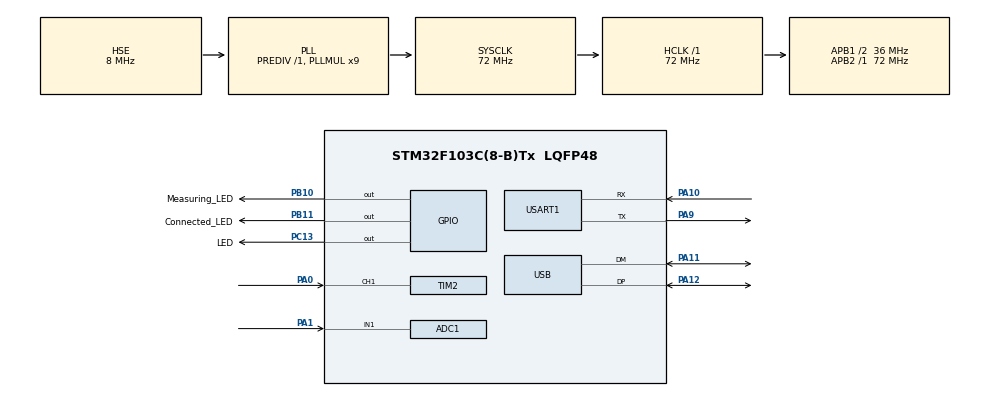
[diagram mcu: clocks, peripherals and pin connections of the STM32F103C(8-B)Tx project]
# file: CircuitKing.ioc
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ADC1.Channel-0\#ChannelRegularConversion=ADC_CHANNEL_1
ADC1.ContinuousConvMode=ENABLE
ADC1.NbrOfConversionFlag=1
ADC1.Rank-0\#ChannelRegularConversion=1
ADC1.SamplingTime-0\#ChannelRegularConversion=ADC_SAMPLETIME_1CYCLE_5
ADC1.master=1
Dma.ADC1.0.Direction=DMA_PERIPH_TO_MEMORY
Dma.ADC1.0.Instance=DMA1_Channel1
Dma.ADC1.0.MemDataAlignment=DMA_MDATAALIGN_HALFWORD
Dma.ADC1.0.MemInc=DMA_MINC_ENABLE
Dma.ADC1.0.Mode=DMA_NORMAL
Dma.ADC1.0.PeriphDataAlignment=DMA_PDATAALIGN_HALFWORD
Dma.ADC1.0.PeriphInc=DMA_PINC_DISABLE
Dma.ADC1.0.Priority=DMA_PRIORITY_LOW
Dma.Request0=ADC1
Mcu.Family=STM32F1
Mcu.Name=STM32F103C(8-B)Tx
Mcu.Package=LQFP48
NVIC.DMA1_Channel1_IRQn=true\:0\:0\:false\:false\:true\:false\:true\:true
NVIC.PriorityGroup=NVIC_PRIORITYGROUP_4
NVIC.TIM2_IRQn=true\:0\:0\:false\:false\:true\:true\:true\:true
NVIC.USB_LP_CAN1_RX0_IRQn=true\:0\:0\:false\:false\:true\:false\:true\:true
PA0-WKUP.Signal=S_TIM2_CH1_ETR
PA1.Signal=ADCx_IN1
PA10.Mode=Asynchronous
PA10.Signal=USART1_RX
PA11.Mode=Device
PA11.Signal=USB_DM
PA12.Mode=Device
PA12.Signal=USB_DP
PA9.Mode=Asynchronous
PA9.Signal=USART1_TX
PB10.GPIO_Label=Measuring_LED
PB10.Signal=GPIO_Output
PB11.GPIO_Label=Connected_LED
PB11.Signal=GPIO_Output
PC13-TAMPER-RTC.GPIO_Label=LED
PC13-TAMPER-RTC.Signal=GPIO_Output
PD0-OSC_IN.Mode=HSE-External-Oscillator
PD0-OSC_IN.Signal=RCC_OSC_IN
PD1-OSC_OUT.Mode=HSE-External-Oscillator
PD1-OSC_OUT.Signal=RCC_OSC_OUT
ProjectManager.HeapSize=0x200
ProjectManager.StackSize=0x400
ProjectManager.TargetToolchain=MDK-ARM V5.32
RCC.ADCPresc=RCC_ADCPCLK2_DIV6
RCC.AHBFreq_Value=72000000
RCC.APB1CLKDivider=RCC_HCLK_DIV2
RCC.APB1Freq_Value=36000000
RCC.APB1TimFreq_Value=72000000
RCC.APB2Freq_Value=72000000
RCC.APB2TimFreq_Value=72000000
RCC.HCLKFreq_Value=72000000
RCC.PLLMUL=RCC_PLL_MUL9
RCC.SYSCLKFreq_VALUE=72000000
RCC.SYSCLKSource=RCC_SYSCLKSOURCE_PLLCLK
RCC.USBFreq_Value=48000000
RCC.USBPrescaler=RCC_USBCLKSOURCE_PLL_DIV1_5
SH.ADCx_IN1.0=ADC1_IN1,IN1
SH.S_TIM2_CH1_ETR.0=TIM2_CH1,Input_Capture1_from_TI1
TIM2.Channel-Input_Capture1_from_TI1=TIM_CHANNEL_1
TIM2.Prescaler=72-1
USART1.VirtualMode=VM_ASYNC
USB_DEVICE.CLASS_NAME_FS=CDC
USB_DEVICE.MANUFACTURER_STRING=CircuitKing
USB_DEVICE.PRODUCT_STRING_CDC_FS=CircuitKing
USB_DEVICE.VirtualMode=Cdc
USB_DEVICE.VirtualModeFS=Cdc_FS
VP_SYS_VS_ND.Mode=No_Debug
VP_TIM2_VS_ClockSourceINT.Mode=Internal
VP_USB_DEVICE_VS_USB_DEVICE_CDC_FS.Mode=CDC_FS
board=custom

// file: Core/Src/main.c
/* USER CODE BEGIN Header */
/**
  ******************************************************************************
  * @file           : main.c
  * @brief          : Main program body
  ******************************************************************************
  * @attention
  *
  * Copyright (c) 2024 STMicroelectronics.
  * All rights reserved.
  *
  * This software is licensed under terms that can be found in the LICENSE file
  * in the root directory of this software component.
  * If no LICENSE file comes with this software, it is provided AS-IS.
  *
  ******************************************************************************
  */
/* USER CODE END Header */
#include "main.h"
#include "usb_device.h"

/* USER CODE BEGIN Includes */
#include "usb_driver.h"
#include "usbd_cdc_if.h"
#include "Communication.h"
/* USER CODE END Includes */

ADC_HandleTypeDef hadc1;
DMA_HandleTypeDef hdma_adc1;

TIM_HandleTypeDef htim2;

UART_HandleTypeDef huart1;

void SystemClock_Config(void);
static void MX_GPIO_Init(void);
static void MX_DMA_Init(void);
static void MX_ADC1_Init(void);
static void MX_TIM2_Init(void);
static void MX_USART1_UART_Init(void);

int main(void)
{

  /* MCU Configuration--------------------------------------------------------*/

  /* Reset of all peripherals, Initializes the Flash interface and the Systick. */
  HAL_Init();

  /* Configure the system clock */
  SystemClock_Config();

  /* Initialize all configured peripherals */
  MX_GPIO_Init();
  MX_DMA_Init();
  MX_ADC1_Init();
  MX_TIM2_Init();
  MX_USB_DEVICE_Init();
  MX_USART1_UART_Init();

  /* Infinite loop */
  while (1)
  {

    /* USER CODE BEGIN 3 */
		if(usb_driver_data_ready == USB_DRIVER_DATA_READY){
			HAL_GPIO_TogglePin(LED_GPIO_Port,LED_Pin);
			communication();
		}

  }
  /* USER CODE END 3 */
}

void SystemClock_Config(void)
{
  RCC_OscInitTypeDef RCC_OscInitStruct = {0};
  RCC_ClkInitTypeDef RCC_ClkInitStruct = {0};
  RCC_PeriphCLKInitTypeDef PeriphClkInit = {0};

  /** Initializes the RCC Oscillators according to the specified parameters
  * in the RCC_OscInitTypeDef structure.
  */
  RCC_OscInitStruct.OscillatorType = RCC_OSCILLATORTYPE_HSE;
  RCC_OscInitStruct.HSEState = RCC_HSE_ON;
  RCC_OscInitStruct.HSEPredivValue = RCC_HSE_PREDIV_DIV1;
  RCC_OscInitStruct.HSIState = RCC_HSI_ON;
  RCC_OscInitStruct.PLL.PLLState = RCC_PLL_ON;
  RCC_OscInitStruct.PLL.PLLSource = RCC_PLLSOURCE_HSE;
  RCC_OscInitStruct.PLL.PLLMUL = RCC_PLL_MUL9;
  if (HAL_RCC_OscConfig(&RCC_OscInitStruct) != HAL_OK)
  {
    Error_Handler();
  }

  /** Initializes the CPU, AHB and APB buses clocks
  */
  RCC_ClkInitStruct.ClockType = RCC_CLOCKTYPE_HCLK|RCC_CLOCKTYPE_SYSCLK
                              |RCC_CLOCKTYPE_PCLK1|RCC_CLOCKTYPE_PCLK2;
  RCC_ClkInitStruct.SYSCLKSource = RCC_SYSCLKSOURCE_PLLCLK;
  RCC_ClkInitStruct.AHBCLKDivider = RCC_SYSCLK_DIV1;
  RCC_ClkInitStruct.APB1CLKDivider = RCC_HCLK_DIV2;
  RCC_ClkInitStruct.APB2CLKDivider = RCC_HCLK_DIV1;

  if (HAL_RCC_ClockConfig(&RCC_ClkInitStruct, FLASH_LATENCY_2) != HAL_OK)
  {
    Error_Handler();
  }
  PeriphClkInit.PeriphClockSelection = RCC_PERIPHCLK_ADC|RCC_PERIPHCLK_USB;
  PeriphClkInit.AdcClockSelection = RCC_ADCPCLK2_DIV6;
  PeriphClkInit.UsbClockSelection = RCC_USBCLKSOURCE_PLL_DIV1_5;
  if (HAL_RCCEx_PeriphCLKConfig(&PeriphClkInit) != HAL_OK)
  {
    Error_Handler();
  }
}

static void MX_ADC1_Init(void)
{

  ADC_ChannelConfTypeDef sConfig = {0};

  /** Common config
  */
  hadc1.Instance = ADC1;
  hadc1.Init.ScanConvMode = ADC_SCAN_DISABLE;
  hadc1.Init.ContinuousConvMode = ENABLE;
  hadc1.Init.DiscontinuousConvMode = DISABLE;
  hadc1.Init.ExternalTrigConv = ADC_SOFTWARE_START;
  hadc1.Init.DataAlign = ADC_DATAALIGN_RIGHT;
  hadc1.Init.NbrOfConversion = 1;
  if (HAL_ADC_Init(&hadc1) != HAL_OK)
  {
    Error_Handler();
  }

  /** Configure Regular Channel
  */
  sConfig.Channel = ADC_CHANNEL_1;
  sConfig.Rank = ADC_REGULAR_RANK_1;
  sConfig.SamplingTime = ADC_SAMPLETIME_1CYCLE_5;
  if (HAL_ADC_ConfigChannel(&hadc1, &sConfig) != HAL_OK)
  {
    Error_Handler();
  }

}

static void MX_TIM2_Init(void)
{

  TIM_ClockConfigTypeDef sClockSourceConfig = {0};
  TIM_MasterConfigTypeDef sMasterConfig = {0};
  TIM_IC_InitTypeDef sConfigIC = {0};

  htim2.Instance = TIM2;
  htim2.Init.Prescaler = 72-1;
  htim2.Init.CounterMode = TIM_COUNTERMODE_UP;
  htim2.Init.Period = 65535;
  htim2.Init.ClockDivision = TIM_CLOCKDIVISION_DIV1;
  htim2.Init.AutoReloadPreload = TIM_AUTORELOAD_PRELOAD_DISABLE;
  if (HAL_TIM_Base_Init(&htim2) != HAL_OK)
  {
    Error_Handler();
  }
  sClockSourceConfig.ClockSource = TIM_CLOCKSOURCE_INTERNAL;
  if (HAL_TIM_ConfigClockSource(&htim2, &sClockSourceConfig) != HAL_OK)
  {
    Error_Handler();
  }
  if (HAL_TIM_IC_Init(&htim2) != HAL_OK)
  {
    Error_Handler();
  }
  sMasterConfig.MasterOutputTrigger = TIM_TRGO_RESET;
  sMasterConfig.MasterSlaveMode = TIM_MASTERSLAVEMODE_DISABLE;
  if (HAL_TIMEx_MasterConfigSynchronization(&htim2, &sMasterConfig) != HAL_OK)
  {
    Error_Handler();
  }
  sConfigIC.ICPolarity = TIM_INPUTCHANNELPOLARITY_RISING;
  sConfigIC.ICSelection = TIM_ICSELECTION_DIRECTTI;
  sConfigIC.ICPrescaler = TIM_ICPSC_DIV1;
  sConfigIC.ICFilter = 0;
  if (HAL_TIM_IC_ConfigChannel(&htim2, &sConfigIC, TIM_CHANNEL_1) != HAL_OK)
  {
    Error_Handler();
  }

}

static void MX_USART1_UART_Init(void)
{

  huart1.Instance = USART1;
  huart1.Init.BaudRate = 115200;
  huart1.Init.WordLength = UART_WORDLENGTH_8B;
  huart1.Init.StopBits = UART_STOPBITS_1;
  huart1.Init.Parity = UART_PARITY_NONE;
  huart1.Init.Mode = UART_MODE_TX_RX;
  huart1.Init.HwFlowCtl = UART_HWCONTROL_NONE;
  huart1.Init.OverSampling = UART_OVERSAMPLING_16;
  if (HAL_UART_Init(&huart1) != HAL_OK)
  {
    Error_Handler();
  }

}

static void MX_DMA_Init(void)
{

  /* DMA controller clock enable */
  __HAL_RCC_DMA1_CLK_ENABLE();

  /* DMA interrupt init */
  /* DMA1_Channel1_IRQn interrupt configuration */
  HAL_NVIC_SetPriority(DMA1_Channel1_IRQn, 0, 0);
  HAL_NVIC_EnableIRQ(DMA1_Channel1_IRQn);

}

static void MX_GPIO_Init(void)
{
  GPIO_InitTypeDef GPIO_InitStruct = {0};

  /* GPIO Ports Clock Enable */
  __HAL_RCC_GPIOC_CLK_ENABLE();
  __HAL_RCC_GPIOD_CLK_ENABLE();
  __HAL_RCC_GPIOA_CLK_ENABLE();
  __HAL_RCC_GPIOB_CLK_ENABLE();

  /*Configure GPIO pin Output Level */
  HAL_GPIO_WritePin(LED_GPIO_Port, LED_Pin, GPIO_PIN_RESET);

  /*Configure GPIO pin Output Level */
  HAL_GPIO_WritePin(GPIOB, Measuring_LED_Pin|Connected_LED_Pin, GPIO_PIN_RESET);

  /*Configure GPIO pin : LED_Pin */
  GPIO_InitStruct.Pin = LED_Pin;
  GPIO_InitStruct.Mode = GPIO_MODE_OUTPUT_PP;
  GPIO_InitStruct.Pull = GPIO_NOPULL;
  GPIO_InitStruct.Speed = GPIO_SPEED_FREQ_LOW;
  HAL_GPIO_Init(LED_GPIO_Port, &GPIO_InitStruct);

  /*Configure GPIO pins : Measuring_LED_Pin Connected_LED_Pin */
  GPIO_InitStruct.Pin = Measuring_LED_Pin|Connected_LED_Pin;
  GPIO_InitStruct.Mode = GPIO_MODE_OUTPUT_PP;
  GPIO_InitStruct.Pull = GPIO_NOPULL;
  GPIO_InitStruct.Speed = GPIO_SPEED_FREQ_LOW;
  HAL_GPIO_Init(GPIOB, &GPIO_InitStruct);

}

void Error_Handler(void)
{
  __disable_irq();
  while (1)
  {
  }
}
